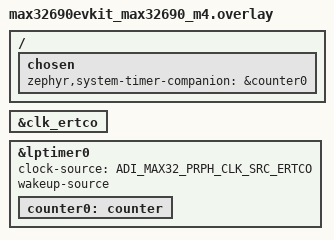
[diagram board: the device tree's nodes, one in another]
/*
 * Copyright (c) 2024 Analog Devices, Inc.
 *
 * SPDX-License-Identifier: Apache-2.0
 */

/ {
	chosen {
		zephyr,system-timer-companion = &counter0;
	};
};

&clk_ertco {
	status = "okay";
};

&lptimer0 {
	clock-source = <ADI_MAX32_PRPH_CLK_SRC_ERTCO>;
	wakeup-source;
	status = "okay";

	counter0: counter {
		status = "okay";
	};
};
